AUTOSAR XML (schema 314)
package /ComponentType
  internal behavior Sa_HwTqCorrln_InternalBehavior: component=Sa_HwTqCorrln
    4 x timing event:
      HwTqCorrln_Init1_InitEvent: start-on-event=HwTqCorrln_Init1, period=0
      TMT_HwTqCorrln_Per1: start-on-event=HwTqCorrln_Per1, period=0.002
      TMT_HwTqCorrln_Per2: start-on-event=HwTqCorrln_Per2, period=0.004
      TMT_HwTqCorrln_Per3: start-on-event=HwTqCorrln_Per3, period=0.1
    per instance memory HwTqCorrlnCh1CMCLPFSvData: type=Float, type-definition=/DataType/Float
    port-api-options:
      enable-take-address=false, indirect-api=false, port=HwTq1Qlfr
      enable-take-address=false, indirect-api=false, port=HwTq1RollgCntr
      enable-take-address=false, indirect-api=false, port=HwTq1Val
      enable-take-address=false, indirect-api=false, port=HwTq2Qlfr
      enable-take-address=false, indirect-api=false, port=HwTq2RollgCntr
      enable-take-address=false, indirect-api=false, port=HwTq2Val
      enable-take-address=false, indirect-api=false, port=HwTqCorrlnCh1CMCLPFSvBlk
      enable-take-address=false, indirect-api=false, port=HwTqCorrlnSts
      enable-take-address=false, indirect-api=false, port=HwTqIdptSig
      enable-take-address=false, indirect-api=false, port=HwTqVal
      enable-take-address=false, indirect-api=false, port=NxtrDiagMgr
    4 x runnable:
      HwTqCorrln_Init1
      HwTqCorrln_Per1
        6 x data read access:
          READ_HwTq1Qlfr_State_enum: data-element=HwTq1Qlfr.State_enum
          READ_HwTq1RollgCntr_Cnt_u08: data-element=HwTq1RollgCntr.Cnt_u08
          READ_HwTq1Val_HwNm_f32: data-element=HwTq1Val.HwNm_f32
          READ_HwTq2Qlfr_State_enum: data-element=HwTq2Qlfr.State_enum
          READ_HwTq2RollgCntr_Cnt_u08: data-element=HwTq2RollgCntr.Cnt_u08
          READ_HwTq2Val_HwNm_f32: data-element=HwTq2Val.HwNm_f32
        data write access WRITE_HwTqCorrlnSts_Cnt_u16: data-element=HwTqCorrlnSts.Cnt_u16
        sync call SC_NxtrDiagMgr_GetNTCActive: operation=NxtrDiagMgr.GetNTCActive, timeout=0
      HwTqCorrln_Per2
        data read access READ_HwTq1Val_HwNm_f32: data-element=HwTq1Val.HwNm_f32
        data read access READ_HwTq2Val_HwNm_f32: data-element=HwTq2Val.HwNm_f32
        data write access WRITE_HwTqIdptSig_Cnt_u08: data-element=HwTqIdptSig.Cnt_u08
        sync call SC_NxtrDiagMgr_GetNTCActive: operation=NxtrDiagMgr.GetNTCActive, timeout=0
        sync call SC_NxtrDiagMgr_SetNTCStatus: operation=NxtrDiagMgr.SetNTCStatus, timeout=0
      HwTqCorrln_Per3
        data read access READ_HwTqVal_HwNm_f32: data-element=HwTqVal.HwNm_f32
        sync call SC_HwTqCorrlnCh1CMCLPFSvBlk_SetRamBlockStatus: operation=HwTqCorrlnCh1CMCLPFSvBlk.SetRamBlockStatus, timeout=0
    service-needss:
      swc nv block needs HwTqCorrlnCh1CMCLPFSvBlk: n-data-sets=0, readonly=false, reliability=LOW, resistant-to-changed-sw=false, restore-at-start=false, write-only-once=false, writing-frequency=0, writing-priority=LOW, mirror-block=HwTqCorrlnCh1CMCLPFSvData
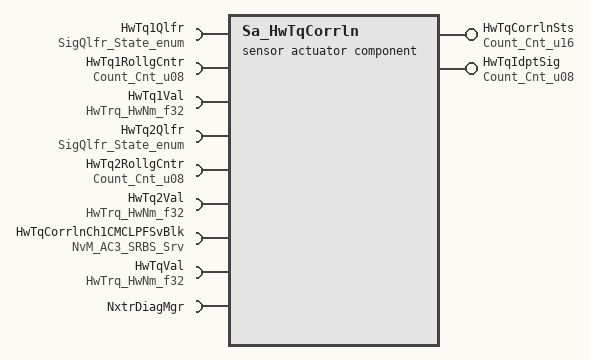
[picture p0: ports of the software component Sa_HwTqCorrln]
  sensor actuator software component type Sa_HwTqCorrln
    provide port HwTqCorrlnSts: unqueued-sender-com-spec{data-element=Cnt_u16, can-invalidate=false, init-value=D_THREE_CNT_U16}, provided-interface=Count_Cnt_u16
    provide port HwTqIdptSig: unqueued-sender-com-spec{data-element=Cnt_u08, can-invalidate=false, init-value=D_FOUR_CNT_U08}, provided-interface=Count_Cnt_u08
    9 x require port:
      HwTq1Qlfr: unqueued-receiver-com-spec{data-element=State_enum, init-value=D_SIGQLFRNORES_CNT_ENUM}, required-interface=SigQlfr_State_enum
      HwTq1RollgCntr: unqueued-receiver-com-spec{data-element=Cnt_u08, init-value=D_ZERO_CNT_U8}, required-interface=Count_Cnt_u08
      HwTq1Val: unqueued-receiver-com-spec{data-element=HwNm_f32, init-value=D_ZERO_ULS_F32}, required-interface=HwTrq_HwNm_f32
      HwTq2Qlfr: unqueued-receiver-com-spec{data-element=State_enum, init-value=D_SIGQLFRNORES_CNT_ENUM}, required-interface=SigQlfr_State_enum
      HwTq2RollgCntr: unqueued-receiver-com-spec{data-element=Cnt_u08, init-value=D_ZERO_CNT_U8}, required-interface=Count_Cnt_u08
      HwTq2Val: unqueued-receiver-com-spec{data-element=HwNm_f32, init-value=D_ZERO_ULS_F32}, required-interface=HwTrq_HwNm_f32
      HwTqCorrlnCh1CMCLPFSvBlk: required-com-specs=[EraseBlock, GetErrorStatus, InvalidateNvBlock, ReadBlock, SetRamBlockStatus, WriteBlock], required-interface=NvM_AC3_SRBS_Srv
      HwTqVal: unqueued-receiver-com-spec{data-element=HwNm_f32, init-value=D_ZERO_ULS_F32}, required-interface=HwTrq_HwNm_f32
      NxtrDiagMgr: required-com-specs=[GetNTCActive, GetNTCFailed, GetNTCStatus, SetNTCStatus], required-interface=NxtrDiagMgr
  swc implementation Sa_HwTqCorrln_Implementation: behavior=Sa_HwTqCorrln_InternalBehavior
    code-descriptors:
      code Code: type=SRC
